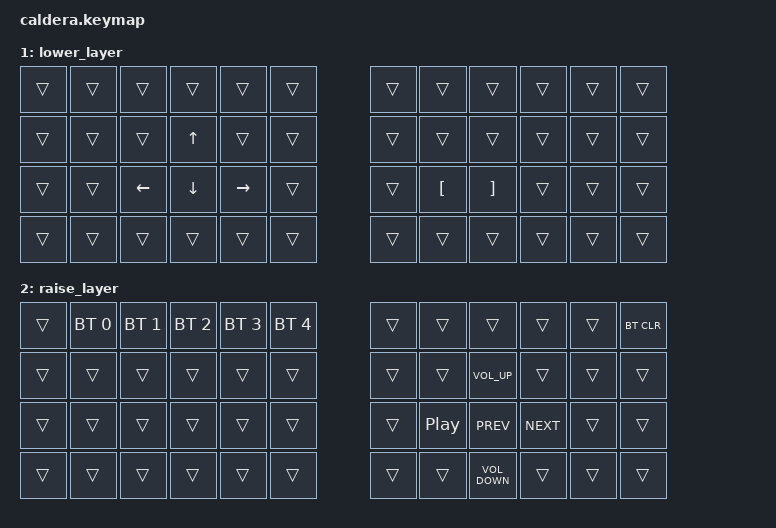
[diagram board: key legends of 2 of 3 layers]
#include <behaviors.dtsi>
#include <dt-bindings/zmk/keys.h>
#include <dt-bindings/zmk/bt.h>

/ {
        keymap {
                compatible = "zmk,keymap";

                default_layer {
// ---------------------------------------------------------------------------------
// |   `  |  1  |  2  |  3  |  4  |  5  |     |  6  |  7  |  8  |  9  |  0  | BKSP |
// |  TAB |  Q  |  W  |  E  |  R  |  T  |     |  Z  |  U  |  I  |  O  |  P  |  \   |
// | CAPS |  A  |  S  |  D  |  F  |  G  |     |  H  |  J  |  K  |  L  |  ;  |  ENT |
// | SHFT |  Y  |  X  |  C  |  V  |  B  |     |  N  |  M  |  ,  |  .  |  /  | APOS |
// | CTRL | ALT | GUI | SPC | SPC | SPC |     | SPC | LOW |LARW |DARW |UARW | RARW |
                        bindings = <
   &kp ESCAPE &kp N1    &kp N2    &kp N3     &kp N4     &kp N5               &kp N6     &kp N7  &kp N8     &kp N9    &kp N0    &kp BSPC
   &kp TAB    &kp Q     &kp W     &kp E      &kp R      &kp T                &kp Z      &kp U   &kp I      &kp O     &kp P     &kp DELETE
   &kp CAPS   &kp A     &kp S     &kp D      &kp F      &kp G                &kp H      &kp J   &kp K      &kp L     &kp SEMI  &kp RETURN
   &kp LSHFT  &kp Y     &kp X     &kp C      &kp V      &kp B                &kp N      &kp M   &kp COMMA  &kp DOT   &kp MINUS &kp RSHFT
   &kp LCTRL  &kp LALT  &kp LGUI  &kp GRAVE  &mo 1      &kp SPACE            &kp SPACE  &mo 2   &kp SLASH  &kp EQUAL &kp APOS  &kp RCTRL
                        >;
                };
                lower_layer {
// ------------------------------------------------------------------------------------------------------------
// |       |       |       |       |       |       |          |       |       |       |       |       | BTCLR |
// |       |       |       | UP    |       |       |          |       |       |       |       |       |       |
// |       |       | LEFT  | DOWN  | RIGHT |       |          |       | LBKT  | RBKT  |       |       |       |
// |       |       |       |       |       |       |          |       |       |       |       |       |       |
                        bindings = <
   &trans    &trans    &trans         &trans         &trans          &trans                 &trans    &trans    &trans   &trans   &trans     &trans
   &trans    &trans    &trans         &kp UP_ARROW   &trans          &trans                 &trans    &trans    &trans   &trans   &trans     &trans
   &trans    &trans    &kp LEFT_ARROW &kp DOWN_ARROW &kp RIGHT_ARROW &trans                 &trans    &kp LBKT  &kp RBKT &trans   &trans     &trans
   &trans    &trans    &trans         &trans         &trans          &trans                 &trans    &trans    &trans   &trans   &trans     &trans
                        >;
                };
                raise_layer {
// ------------------------------------------------------------------------------------------------------------
// |       |  BT1  |  BT2  |  BT3  |  BT4  |  BT5  |          |       |       |       |       |       | BTCLR |
// |       |       |       |       |       |       |          |       |       |       |       |       |       |
// |       |       |       | LPAR  | RPAR  |       |          |       | LBKT  | RBKT  |       |       |       |
// |       |       |       |       |       |       |          |       |       |       |       |       |       |
                        bindings = <
   &trans    &bt BT_SEL 0   &bt BT_SEL 1   &bt BT_SEL 2   &bt BT_SEL 3   &bt BT_SEL 4           &trans    &trans    &trans   &trans   &trans  &bt BT_CLR
   &trans    &trans         &trans         &trans         &trans         &trans                 &trans    &trans    &kp C_VOLUME_UP   &trans   &trans  &trans
   &trans    &trans         &trans         &trans         &trans         &trans                 &trans    &kp C_PLAY_PAUSE   &kp C_PREV &kp C_NEXT   &trans  &trans
   &trans    &trans         &trans         &trans         &trans         &trans                 &trans    &trans    &kp C_VOLUME_DOWN   &trans   &trans  &trans
                        >;
                };
        };
};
